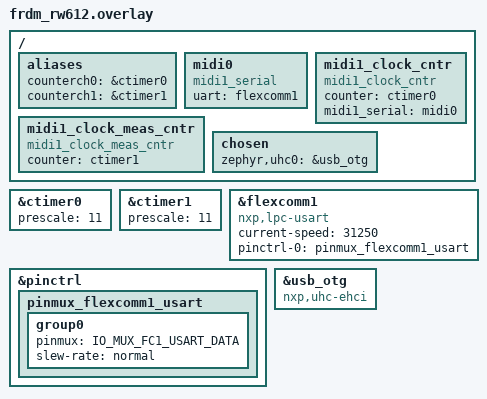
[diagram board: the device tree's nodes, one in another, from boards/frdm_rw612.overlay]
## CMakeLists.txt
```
# SPDX-License-Identifier: Apache-2.0

cmake_minimum_required(VERSION 3.20.0)

find_package(Zephyr REQUIRED HINTS $ENV{ZEPHYR_BASE})
project(midi1_joystick)

target_sources(app PRIVATE 
    src/main.c
    src/midi_bridge.c
    src/joystick_hid.c
)

target_sources_ifdef(CONFIG_SOC_FAMILY_MCXN app PRIVATE src/usb_host_init.c)
target_sources_ifdef(CONFIG_SOC_SERIES_MCXA app PRIVATE src/usb_host_init.c)

target_include_directories(app PRIVATE src)
```

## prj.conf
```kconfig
CONFIG_USB_HOST_STACK=y
CONFIG_UHC_DRIVER=y
CONFIG_USBH_LOG_LEVEL_INF=y

CONFIG_LOG=y
CONFIG_MAIN_STACK_SIZE=10240
CONFIG_HEAP_MEM_POOL_SIZE=16384

# USB Host Settings
CONFIG_UHC_XFER_COUNT=8
CONFIG_UHC_BUF_COUNT=16
CONFIG_UHC_BUF_POOL_SIZE=2048
CONFIG_USBH_USB_DEVICE_HEAP=4096
CONFIG_USBH_STACK_SIZE=4096
CONFIG_UHC_NXP_THREAD_STACK_SIZE=2048

# Stack protection
CONFIG_STACK_SENTINEL=y

# MIDI1 related
CONFIG_MIDI1_SERIAL=y
```

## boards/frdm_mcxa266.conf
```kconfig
CONFIG_UHC_NXP_KHCI=y
CONFIG_USBH_LOG_LEVEL_DBG=y
CONFIG_UHC_DRIVER_LOG_LEVEL_DBG=y

# Optimized stack sizes
CONFIG_MAIN_STACK_SIZE=2048
CONFIG_USBH_STACK_SIZE=4096
CONFIG_UHC_NXP_THREAD_STACK_SIZE=2048

# Optimized memory pools for Host
CONFIG_USBH_USB_DEVICE_HEAP=2048
CONFIG_UHC_BUF_POOL_SIZE=4096
CONFIG_UHC_XFER_COUNT=8
CONFIG_UHC_BUF_COUNT=16
CONFIG_HEAP_MEM_POOL_SIZE=4096
CONFIG_HEAP_MEM_POOL_ADD_SIZE_UHC_MCUX=4096

# Regulator support for VBUS enable
CONFIG_REGULATOR=y

# Silence ADC warnings (board defconfig enables calibration but not the driver)
CONFIG_LPADC_DO_OFFSET_CALIBRATION=n
```

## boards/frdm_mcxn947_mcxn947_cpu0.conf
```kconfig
# FRDM-MCXN947 specific configuration
CONFIG_MAIN_STACK_SIZE=2048
CONFIG_USBH_STACK_SIZE=4096
CONFIG_USBH_USB_DEVICE_HEAP=2048
CONFIG_UHC_DRIVER_LOG_LEVEL_DBG=y
CONFIG_USBH_LOG_LEVEL_DBG=y
CONFIG_USB_HOST_STACK=y
# EHCI requires some heap for transfers
CONFIG_HEAP_MEM_POOL_ADD_SIZE_UHC_MCUX=4096
CONFIG_HEAP_MEM_POOL_SIZE=4096
```

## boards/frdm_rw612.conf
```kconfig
CONFIG_UHC_NXP_EHCI=y
```

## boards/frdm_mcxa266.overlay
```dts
/**
 * Device tree overlay for the FRDM-MCXA266 development kit.
 * Configures Arduino D0/D1 (LPUART2) for MIDI and enables USB Host.
 * 
 * @author Jan-Willem Smaal <usenet@gispen.org>
 * @date 20260513
 * license SPDX-License-Identifier: Apache-2.0
 */

&ctimer0 {
	status = "okay";
};

&ctimer1 {
	status = "okay";
};

/* 
 * MIDI on Arduino D0/D1 (P2_3/P2_2) 
 */
&lpuart2 {
	status = "okay";
	current-speed = <31250>;
	pinctrl-0 = <&pinmux_lpuart2>;
	pinctrl-names = "default";
};

/* 
 * USB Host (KHCI) 
 * We switch the compatible to the host driver (uhc-khci).
 * We must delete 'num-bidir-endpoints' and 'no-voltage-regulator' 
 * because they are specific to the device-mode (UDC) driver and 
 * would cause devicetree validation errors when using the host driver.
 */
&usb {
	status = "okay";
	compatible = "nxp,uhc-khci";
	/delete-property/ num-bidir-endpoints;
	/delete-property/ no-voltage-regulator;
};

/ {
	aliases {
		counterch0 = &ctimer0;
		counterch1 = &ctimer1;
	};

	vbus_en: regulator-vbus {
		compatible = "regulator-fixed";
		regulator-name = "vbus_en";
		/* P3_24 (PT3_24) is the direct override pin for NX5P_EN via R92.
		 * Trying direct control to bypass PTN5150 logic.
		 */
		enable-gpios = <&gpio3 24 GPIO_ACTIVE_HIGH>;
		regulator-boot-on;
		regulator-always-on;
	};

	midi0: midi0 {
		status = "okay";
		compatible = "midi1_serial";
		uart = <&lpuart2>;
	};

	midi1_clock_cntr: midi1_clock_cntr {
		status = "okay";
		compatible = "midi1_clock_cntr";
		counter = <&ctimer0>;
		midi1_serial = <&midi0>;
	};

	midi1_clock_meas_cntr: midi1_clock_meas_cntr {
		status = "okay";
		compatible = "midi1_clock_meas_cntr";
		counter = <&ctimer1>;
	};

	chosen {
		zephyr,uhc0 = &usb;
	};
};
```

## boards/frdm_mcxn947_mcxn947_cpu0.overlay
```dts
/*
 * Device tree overlay for FRDM-MCXN947
 * @author Jan-Willem Smaal <usenet@gispen.org>
 */

/ {
	chosen {
		zephyr,uhc0 = &usb1;
	};

	aliases {
		counterch0 = &ctimer0;
		counterch1 = &ctimer1;
	};

	/* VBUS power enable for USB Host mode (J11 connector) */
	vbus_reg: regulator-fixed {
		compatible = "regulator-fixed";
		regulator-name = "vbus_reg";
		/* UM12018 Page 26: P4_16 is USB1_OTG_PWR */
		enable-gpios = <&gpio4 16 GPIO_ACTIVE_HIGH>;
		regulator-boot-on;
		regulator-always-on;
	};

	midi0: midi0 {
		status = "okay";
		compatible = "midi1_serial";
		uart = <&flexcomm2_lpuart2>;
	};

	midi1_clock_cntr: midi1_clock_cntr {
		status = "okay";
		compatible = "midi1_clock_cntr";
		counter = <&ctimer0>;
		midi1_serial = <&midi0>;
	};

	midi1_clock_meas_cntr: midi1_clock_meas_cntr {
		status = "okay";
		compatible = "midi1_clock_meas_cntr";
		counter = <&ctimer1>;
	};
};

/* High-Speed USB Host */
&usb1 {
	status = "okay";
	compatible = "nxp,uhc-ehci";
	phy-handle = <&usbphy1>;
	/delete-property/ num-bidir-endpoints;
};

&usbphy1 {
	status = "okay";
};

/* MIDI on Arduino D0/D1 */
&flexcomm2_lpuart2 {
	status = "okay";
	current-speed = <31250>;
};

&ctimer0 {
	status = "okay";
};

&ctimer1 {
	status = "okay";
};
```

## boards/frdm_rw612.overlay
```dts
/**
 * Device tree overlay created for the FRDM_RW612 development kit
 * adjusted the pinmux so that we can use it for MIDI out and in.
 * @author Jan-Willem Smaal <usenet@gispen.org>
 * @date 20241223
 * updated in 20260206
 * license SPDX-License-Identifier: Apache-2.0
 */
 
 /* Let's make sure both are enabled and act in the same way as the pit0 */
&ctimer0 {
	status = "okay";
	/* Divide 260 MHz by 4 → 24 MHz timer */
	prescale = <11>;
};
&ctimer1 {
	status = "okay";
	/* Divide 260 MHz by 4 → 24 MHz timer */
	prescale = <11>;
};

/* 
 * Configured with the MIDI BAUD rate of 31250 
 * This is the USART on the MIDI arduino shield. 
 * GPIO 8 and 9. 
 */
&flexcomm1 {
	compatible = "nxp,lpc-usart";
	status = "okay";
	current-speed = <31250>;
	pinctrl-0 = <&pinmux_flexcomm1_usart>;
	pinctrl-names = "default";
};

/* 
 * We want to set flexcomm1 to USART instead of the default. 
 * this is why we need to set the pinmux here. 
 */
&pinctrl {
	pinmux_flexcomm1_usart: pinmux_flexcomm1_usart {
		group0 {
			pinmux = <IO_MUX_FC1_USART_DATA>;
			slew-rate = "normal";
		};
	};
};

&usb_otg {
	status = "okay";
	compatible = "nxp,uhc-ehci";
	/delete-property/ num-bidir-endpoints;
};


/ {
	aliases {
		counterch0 = &ctimer0;
		counterch1 = &ctimer1;
	};
	/* MIDI1.0 serial USART driver, set the uart baud to 31250. */
	midi0: midi0 {
		status = "okay";
		compatible = "midi1_serial";
		uart = <&flexcomm1>;
	};
	/* MIDI1.0 clock generator for SERIAL MIDI1.0 */
	midi1_clock_cntr: midi1_clock_cntr {
		status = "okay";
		compatible = "midi1_clock_cntr";
		counter = <&ctimer0>;
		midi1_serial = <&midi0>;
	};
	/* MIDI1.0 clock measurement system using the Zephyr timer */
	midi1_clock_meas_cntr: midi1_clock_meas_cntr {
		status = "okay";
		compatible = "midi1_clock_meas_cntr";
		counter = <&ctimer1>;
	};
	chosen {
		zephyr,uhc0 = &usb_otg;
	};
};
```

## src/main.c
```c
/*
 * main.c - USB HID Joystick to MIDI Bridge Entry Point
 *
 * @author Jan-Willem Smaal <usenet@gispen.org>
 *
 * SPDX-License-Identifier: Apache-2.0
 */

#include <zephyr/kernel.h>
#include <zephyr/usb/usbh.h>
#include <zephyr/logging/log.h>

#include "midi_bridge.h"
#include "joystick_hid.h"

LOG_MODULE_REGISTER(main, LOG_LEVEL_INF);

/* USB Host Context */
USBH_CONTROLLER_DEFINE(my_uhs_ctx, DEVICE_DT_GET(DT_CHOSEN(zephyr_uhc0)));

/* Register the Joystick HID Class Driver */
JOYSTICK_HID_CLASS_DEFINE(joystick_host);

int main(void)
{
	int ret;

	LOG_INF("Starting USB HID Joystick Host sample");

	/* 1. Initialize MIDI Bridge */
	ret = midi_bridge_init();
	if (ret != 0) {
		LOG_ERR("Failed to initialize MIDI bridge (%d)", ret);
		/* Continue anyway to allow USB debugging */
	}

	/* 2. Initialize USB Host Stack */
	ret = usbh_init(&my_uhs_ctx);
	if (ret != 0) {
		LOG_ERR("Failed to initialize USB host (%d)", ret);
		return 0;
	}

	/* 3. Enable USB Host Stack */
	ret = usbh_enable(&my_uhs_ctx);
	if (ret != 0) {
		LOG_ERR("Failed to enable USB host (%d)", ret);
		return 0;
	}

	LOG_INF("USB host stack enabled. Waiting for device...");

	while (1) {
		k_sleep(K_MSEC(1000));
	}

	return 0;
}
```

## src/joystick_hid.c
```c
/*
 * joystick_hid.c - USB Host HID Class Driver for T.16000M
 *
 * @author Jan-Willem Smaal <usenet@gispen.org>
 *
 * SPDX-License-Identifier: Apache-2.0
 */

#include <zephyr/kernel.h>
#include <zephyr/sys/byteorder.h>
#include <zephyr/usb/usbh.h>
#include <zephyr/usb/usb_ch9.h>
#include <zephyr/usb/class/hid.h>
#include <zephyr/drivers/usb/uhc.h>
#include <zephyr/logging/log.h>

#include "midi_bridge.h"
#include "joystick_hid.h"

LOG_MODULE_DECLARE(main, LOG_LEVEL_INF);

/* HID Host private data */
struct hid_host_data {
	struct usb_device *udev;
	const struct device *uhc_dev;
	uint8_t ep_in;
	uint16_t mps_in;
	struct uhc_transfer *xfer_in;
};

struct hid_host_data joystick_hid_data;

/**
 * @brief Checks if the received USB transfer contains a valid joystick report
 */
static bool is_valid_joystick_report(struct uhc_transfer *const xfer, 
				     struct hid_host_data *data)
{
	if (xfer->ep != data->ep_in) {
		return false;
	}

	if (xfer->buf == NULL) {
		return false;
	}

	if (xfer->buf->len < 9) {
		return false;
	}

	return true;
}

/**
 * @brief Parse the raw 9-byte T.16000M report into a joystick state
 */
static void handle_joystick_report(struct uhc_transfer *const xfer)
{
	struct joystick_state state;

	/* T.16000M mapping:
	 * Byte 0-1: Buttons
	 * Byte 3-4: X (14-bit LE)
	 * Byte 5-6: Y (14-bit LE)
	 * Byte 7:   Twist (8-bit)
	 * Byte 8:   Fader (8-bit)
	 */
	state.buttons = sys_get_le16(&xfer->buf->data[0]);
	state.x = sys_get_le16(&xfer->buf->data[3]) & 0x3FFF;
	state.y = sys_get_le16(&xfer->buf->data[5]) & 0x3FFF;
	state.twist = xfer->buf->data[7];
	state.fader = xfer->buf->data[8];

	/* Pass high-level state to the MIDI bridge */
	midi_bridge_process(&state);
}

static int hid_host_udev_cb(struct usb_device *const udev,
			    struct uhc_transfer *const xfer)
{
	struct usbh_context *uhs_ctx_ptr = udev->ctx;
	const struct device *uhc_dev = uhs_ctx_ptr->dev;
	struct hid_host_data *data = &joystick_hid_data;

	if (xfer->err != 0) {
		LOG_ERR("USB Transfer failed: %d", xfer->err);
	} else if (is_valid_joystick_report(xfer, data)) {
		handle_joystick_report(xfer);
	} else {
		/* Discard unknown or incomplete packet */
	}

	/* Always resubmit to keep polling */
	if (xfer->buf != NULL) {
		net_buf_reset(xfer->buf);
	}

	if (uhc_ep_enqueue(uhc_dev, xfer) != 0) {
		LOG_ERR("Failed to resubmit IN transfer");
	}

	return 0;
}

static int hid_host_probe(struct usbh_class_data *const c_data,
			  struct usb_device *const udev,
			  const uint8_t iface)
{
	struct hid_host_data *data = c_data->priv;
	struct usbh_context *uhs_ctx = udev->ctx;
	const struct device *uhc_dev = uhs_ctx->dev;

	if (iface == 0xFF) {
		return -ENOTSUP;
	}

	LOG_INF("Probing Joystick VID=0x%04x PID=0x%04x (Interface %u)",
		udev->dev_desc.idVendor, udev->dev_desc.idProduct, iface);

	data->udev = udev;
	data->uhc_dev = uhc_dev;
	data->ep_in = 0;

	/* Find Interrupt IN endpoint */
	for (int i = 0; i < 16; i++) {
		if (udev->ep_in[i].desc != NULL &&
		    (udev->ep_in[i].desc->bmAttributes & USB_EP_TRANSFER_TYPE_MASK) ==
		    USB_EP_TYPE_INTERRUPT) {
			data->ep_in = udev->ep_in[i].desc->bEndpointAddress;
			data->mps_in = sys_le16_to_cpu(udev->ep_in[i].desc->wMaxPacketSize);
			LOG_INF("Found Interrupt IN endpoint 0x%02x, MPS %u", data->ep_in, data->mps_in);
			break;
		}
	}

	if (data->ep_in == 0) {
		LOG_WRN("No Interrupt IN endpoint found for HID interface");
		return -ENOTSUP;
	}

	data->xfer_in = uhc_xfer_alloc_with_buf(uhc_dev, data->ep_in, udev,
					       hid_host_udev_cb, data,
					       data->mps_in);
	if (data->xfer_in == NULL) {
		LOG_ERR("Failed to allocate USB transfer buffer");
		return -ENOMEM;
	}

	if (uhc_ep_enqueue(uhc_dev, data->xfer_in) != 0) {
		LOG_ERR("Failed to submit initial USB transfer");
		uhc_xfer_free(uhc_dev, data->xfer_in);
		data->xfer_in = NULL;
		return -EIO;
	}

	return 0;
}

static int hid_host_removed(struct usbh_class_data *const c_data)
{
	struct hid_host_data *data = c_data->priv;
	LOG_INF("Joystick disconnected");

	if (data->xfer_in != NULL) {
		uhc_xfer_free(data->uhc_dev, data->xfer_in);
		data->xfer_in = NULL;
	}

	data->udev = NULL;
	return 0;
}

static int hid_host_init(struct usbh_class_data *const c_data)
{
	return 0;
}

struct usbh_class_api hid_host_class_api = {
	.init = hid_host_init,
	.probe = hid_host_probe,
	.removed = hid_host_removed,
};
```

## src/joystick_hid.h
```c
/*
 * joystick_hid.h - USB Host HID Class Driver for T.16000M
 *
 * @author Jan-Willem Smaal <usenet@gispen.org>
 *
 * SPDX-License-Identifier: Apache-2.0
 */

#ifndef JOYSTICK_HID_H
#define JOYSTICK_HID_H

#include <zephyr/usb/usbh.h>

/**
 * @brief Macro to define the joystick HID class driver
 * 
 * This should be used in the main.c file to register the driver
 * with the USB host stack.
 */
#define JOYSTICK_HID_CLASS_DEFINE(name) \
	USBH_DEFINE_CLASS(name, &hid_host_class_api, &joystick_hid_data, NULL)

extern struct usbh_class_api hid_host_class_api;
extern struct hid_host_data joystick_hid_data;

#endif /* JOYSTICK_HID_H */
```

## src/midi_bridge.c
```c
/*
 * midi_bridge.c - MIDI translation logic for joystick inputs
 *
 * @author Jan-Willem Smaal <usenet@gispen.org>
 *
 * SPDX-License-Identifier: Apache-2.0
 */

#include <zephyr/kernel.h>
#include <zephyr/device.h>
#include <zephyr/drivers/midi/midi1.h>
#include <zephyr/drivers/midi/midi1_serial.h>
#include <zephyr/logging/log.h>
#include "midi_bridge.h"

LOG_MODULE_DECLARE(main, LOG_LEVEL_INF);

static const struct device *midi_dev;
static const struct midi1_serial_api *mid;

static uint16_t last_buttons;
static uint8_t last_fader;
static uint16_t last_pw;
static uint8_t last_mod;
static uint8_t last_cutoff;

int midi_bridge_init(void)
{
	int ret = 0;

	midi_dev = DEVICE_DT_GET(DT_NODELABEL(midi0));
	if (device_is_ready(midi_dev)) {
		printk("MIDI device %s is ready\n", midi_dev->name);
		ret = 0;
	} else {
		LOG_ERR("MIDI device not ready");
		ret = -ENODEV;
	}
	/* Assign api pointer */
	mid = midi_dev->api;

	return ret;
}

static void process_axes(const struct joystick_state *state)
{
	uint16_t current_pw = state->x;
	uint8_t current_mod = 0;
	uint8_t current_cutoff = state->twist >> 1;

	/* 
	 * MOD WHEEL: Only forward Y axis push (Stick Forward)
	 * T.16000M "Forward" values are < 8192 (Neutral is 8192).
	 */
	if (state->y < 8192) {
		/* Scale [8191 center down to 0 full push] to [1 up to 127] */
		uint16_t delta = 8192 - state->y;
		current_mod = (uint8_t)(delta >> 6);
		if (current_mod > 127) {
			current_mod = 127;
		}
	} else {
		/* Neutral or pulled back */
		current_mod = 0;
	}

	if (device_is_ready(midi_dev)) {
		/* Send Pitchwheel if changed */
		if (current_pw != last_pw) {
			mid->pitchwheel(midi_dev, 
					CONFIG_MIDI1_SERIAL_CHANNEL -1, 
					current_pw);
			printk("STICK X:%-5u | MIDI -> PitchWheel:%-5u\n", state->x, current_pw);
			last_pw = current_pw;
		}

		/* Send Modulation Wheel if changed */
		if (current_mod != last_mod) {
			mid->control_change(midi_dev, 
					    CONFIG_MIDI1_SERIAL_CHANNEL -1, 
					    CTL_MSB_MODWHEEL, 
					    current_mod);
			printk("STICK Y:%-5u | MIDI -> ModWheel:%-3u\n", state->y, current_mod);
			last_mod = current_mod;
		}


		/* Filter Cutoff (Twist/Yaw) -> CC 74 */
		if (current_cutoff != last_cutoff) {
			mid->control_change(midi_dev, 
				            CONFIG_MIDI1_SERIAL_CHANNEL -1, 
					    CTL_SC5_BRIGHTNESS, 
					    current_cutoff);
			printk("STICK T:%-3u   | MIDI -> FilterCutoff:%-3u\n", state->twist, current_cutoff);
			last_cutoff = current_cutoff;
		}
	}
}

static void process_fader(const struct joystick_state *state)
{
	if (state->fader != last_fader) {
		if (device_is_ready(midi_dev)) {
			/* Invert fader: Forward (0) = 127, Back (255) = 0 */
			uint8_t current_vol = 127 - (state->fader >> 1);
			mid->control_change(midi_dev, 
					    CONFIG_MIDI1_SERIAL_CHANNEL -1, 
					    CTL_MSB_MAIN_VOLUME, 
					    current_vol);
			printk("STICK FADER:%-3u    | MIDI -> VOL:%-3u\n",
			       state->fader, current_vol);
		}
		last_fader = state->fader;
	}
}

static void handle_button_note(uint8_t button_idx, bool pressed)
{
	/* Map 12 buttons to chromatic octave starting at C4 (Note 60) */
	uint8_t note = 60 + button_idx;

	if (device_is_ready(midi_dev)) {
		if (pressed) {
			mid->note_on(midi_dev, 
				     CONFIG_MIDI1_SERIAL_CHANNEL -1, 
				     note, 
				     100);
			printk("BUTTON %u:DOWN    | MIDI -> NOTE %u ON\n", button_idx, note);
		} else {
			mid->note_off(midi_dev, 
				      CONFIG_MIDI1_SERIAL_CHANNEL -1, 
				      note, 
				      100);
			printk("BUTTON %u:UP      | MIDI -> NOTE %u OFF\n", button_idx, note);
		}
	}
}

static void process_buttons(const struct joystick_state *state)
{
	/* Process 12 buttons (Bit 0 to 11) */
	for (uint8_t i = 0; i < 12; i++) {
		uint16_t mask = BIT(i);
		bool current_pressed = (state->buttons & mask) != 0;
		bool last_pressed = (last_buttons & mask) != 0;

		if (current_pressed != last_pressed) {
			handle_button_note(i, current_pressed);
		}
	}
	last_buttons = state->buttons;
}

void midi_bridge_process(const struct joystick_state *state)
{
	process_axes(state);
	process_fader(state);
	process_buttons(state);
}

/* EOF */ 
```

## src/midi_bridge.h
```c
/*
 * midi_bridge.h - MIDI translation logic for joystick inputs
 *
 * @author Jan-Willem Smaal <usenet@gispen.org>
 *
 * SPDX-License-Identifier: Apache-2.0
 */

#ifndef MIDI_BRIDGE_H
#define MIDI_BRIDGE_H

#include <zephyr/kernel.h>
#include <stdint.h>

/**
 * @brief Structure representing the state of the joystick
 */
struct joystick_state {
	uint16_t x;
	uint16_t y;
	uint16_t buttons;
	uint8_t twist;
	uint8_t fader;
};

/**
 * @brief Initialize the MIDI bridge subsystem
 * 
 * @return 0 on success, negative error code otherwise
 */
int midi_bridge_init(void);

/**
 * @brief Process a new joystick state and send corresponding MIDI messages
 * 
 * @param state Pointer to the current joystick state
 */
void midi_bridge_process(const struct joystick_state *state);

#endif /* MIDI_BRIDGE_H */
```

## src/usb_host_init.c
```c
/*
 * Copyright 2024-2026 NXP
 * SPDX-License-Identifier: Apache-2.0
 *
 * @file usb_host_init.c
 * @author Jan-Willem Smaal <usenet@gispen.org>
 * @date May 15, 2026
 *
 * This file provides manual initialization for USB Host controllers
 * on NXP MCX series boards. The standard board support in Zephyr
 * often gates these clocks unless Device mode is explicitly enabled.
 */

#include <zephyr/init.h>
#include <zephyr/device.h>
#include <fsl_clock.h>
#include <soc.h>

#ifdef CONFIG_SOC_FAMILY_MCXN
#include <fsl_spc.h>
#define BOARD_XTAL0_CLK_HZ 24000000U
#endif

static int usb_host_clock_init(void)
{
#ifdef CONFIG_SOC_FAMILY_MCXN
	/* MCXN947 High-Speed (EHCI) Initialization */
	
	/* Active mode voltage for OverDrive mode is required for HS USB */
	SPC0->ACTIVE_VDELAY = 0x0500;
	SPC0->ACTIVE_CFG &= ~SPC_ACTIVE_CFG_CORELDO_VDD_DS_MASK;
	SPC0->ACTIVE_CFG |= SPC_ACTIVE_CFG_DCDC_VDD_LVL(0x3) | SPC_ACTIVE_CFG_CORELDO_VDD_LVL(0x3) |
			    SPC_ACTIVE_CFG_SYSLDO_VDD_DS_MASK | SPC_ACTIVE_CFG_DCDC_VDD_DS(0x2u);
	while (SPC0->SC & SPC_SC_BUSY_MASK) { };

	if (0u == (SCG0->LDOCSR & SCG_LDOCSR_LDOEN_MASK)) {
		SCG0->TRIM_LOCK = 0x5a5a0001U;
		SCG0->LDOCSR |= SCG_LDOCSR_LDOEN_MASK;
		while (0U == (SCG0->LDOCSR & SCG_LDOCSR_VOUT_OK_MASK)) { };
	}

	SYSCON->AHBCLKCTRLSET[2] |= SYSCON_AHBCLKCTRL2_USB_HS_MASK |
				    SYSCON_AHBCLKCTRL2_USB_HS_PHY_MASK;

	SCG0->SOSCCFG &= ~(SCG_SOSCCFG_RANGE_MASK | SCG_SOSCCFG_EREFS_MASK);
	SCG0->SOSCCFG = (1U << SCG_SOSCCFG_RANGE_SHIFT) | (1U << SCG_SOSCCFG_EREFS_SHIFT);
	SCG0->SOSCCSR |= SCG_SOSCCSR_SOSCEN_MASK;
	while (!(SCG0->SOSCCSR & SCG_SOSCCSR_SOSCVLD_MASK)) { };

	SYSCON->CLOCK_CTRL |= SYSCON_CLOCK_CTRL_CLKIN_ENA_MASK |
			      SYSCON_CLOCK_CTRL_CLKIN_ENA_FM_USBH_LPT_MASK;

	CLOCK_EnableClock(kCLOCK_UsbHs);
	CLOCK_EnableClock(kCLOCK_UsbHsPhy);
	CLOCK_EnableUsbhsPhyPllClock(kCLOCK_Usbphy480M, BOARD_XTAL0_CLK_HZ);
	CLOCK_EnableUsbhsClock();
#endif

	return 0;
}

/* Run before USB driver init (POST_KERNEL, 50) */
SYS_INIT(usb_host_clock_init, POST_KERNEL, 40);
```
